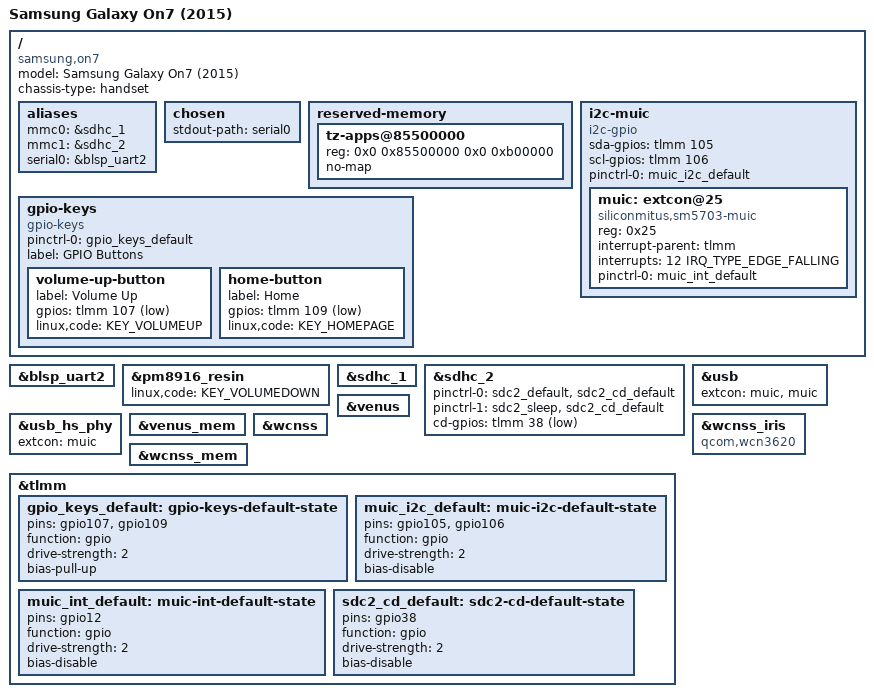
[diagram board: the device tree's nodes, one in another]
// SPDX-License-Identifier: GPL-2.0-only

/dts-v1/;

#include "msm8916-pm8916.dtsi"
#include <dt-bindings/gpio/gpio.h>
#include <dt-bindings/interrupt-controller/irq.h>

/ {
	model = "Samsung Galaxy On7 (2015)";
	compatible = "samsung,on7", "qcom,msm8916";
	chassis-type = "handset";

	aliases {
		mmc0 = &sdhc_1; /* eMMC */
		mmc1 = &sdhc_2; /* SD card */
		serial0 = &blsp_uart2;
	};

	chosen {
		stdout-path = "serial0";
	};

	reserved-memory {
		/* Additional memory used by Samsung firmware modifications */
		tz-apps@85500000 {
			reg = <0x0 0x85500000 0x0 0xb00000>;
			no-map;
		};
	};

	gpio-keys {
		compatible = "gpio-keys";

		pinctrl-0 = <&gpio_keys_default>;
		pinctrl-names = "default";

		label = "GPIO Buttons";

		volume-up-button {
			label = "Volume Up";
			gpios = <&tlmm 107 GPIO_ACTIVE_LOW>;
			linux,code = <KEY_VOLUMEUP>;
		};

		home-button {
			label = "Home";
			gpios = <&tlmm 109 GPIO_ACTIVE_LOW>;
			linux,code = <KEY_HOMEPAGE>;
		};
	};

	i2c-muic {
		compatible = "i2c-gpio";
		sda-gpios = <&tlmm 105 (GPIO_ACTIVE_HIGH|GPIO_OPEN_DRAIN)>;
		scl-gpios = <&tlmm 106 (GPIO_ACTIVE_HIGH|GPIO_OPEN_DRAIN)>;

		pinctrl-0 = <&muic_i2c_default>;
		pinctrl-names = "default";

		#address-cells = <1>;
		#size-cells = <0>;

		muic: extcon@25 {
			compatible = "siliconmitus,sm5703-muic";
			reg = <0x25>;

			interrupt-parent = <&tlmm>;
			interrupts = <12 IRQ_TYPE_EDGE_FALLING>;

			pinctrl-0 = <&muic_int_default>;
			pinctrl-names = "default";
		};
	};
};

&blsp_uart2 {
	status = "okay";
};

&pm8916_resin {
	linux,code = <KEY_VOLUMEDOWN>;
	status = "okay";
};

&sdhc_1 {
	status = "okay";
};

&sdhc_2 {
	pinctrl-0 = <&sdc2_default &sdc2_cd_default>;
	pinctrl-1 = <&sdc2_sleep &sdc2_cd_default>;
	pinctrl-names = "default", "sleep";

	cd-gpios = <&tlmm 38 GPIO_ACTIVE_LOW>;

	status = "okay";
};

&usb {
	extcon = <&muic>, <&muic>;
	status = "okay";
};

&usb_hs_phy {
	extcon = <&muic>;
};

&venus {
	status = "okay";
};

&venus_mem {
	status = "okay";
};

&wcnss {
	status = "okay";
};

&wcnss_iris {
	compatible = "qcom,wcn3620";
};

&wcnss_mem {
	status = "okay";
};

&tlmm {
	gpio_keys_default: gpio-keys-default-state {
		pins = "gpio107", "gpio109";
		function = "gpio";
		drive-strength = <2>;
		bias-pull-up;
	};

	muic_i2c_default: muic-i2c-default-state {
		pins = "gpio105", "gpio106";
		function = "gpio";
		drive-strength = <2>;
		bias-disable;
	};

	muic_int_default: muic-int-default-state {
		pins = "gpio12";
		function = "gpio";
		drive-strength = <2>;
		bias-disable;
	};

	sdc2_cd_default: sdc2-cd-default-state {
		pins = "gpio38";
		function = "gpio";
		drive-strength = <2>;
		bias-disable;
	};
};
